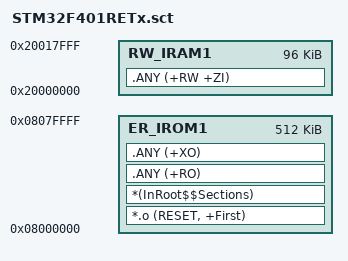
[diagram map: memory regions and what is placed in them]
; *************************************************************
; ** Scatter-Loading Description File generated by RTE CMSIS Plug-in **
; *************************************************************

LR_IROM1 0x8000000 0x80000 {    ; load region size_region
  ER_IROM1 0x8000000 0x80000 {  ; load address = execution address
   *.o (RESET, +First)
   *(InRoot$$Sections)
   .ANY (+RO)
   .ANY (+XO)
  }
  RW_IRAM1 0x20000000 0x18000 {
   .ANY (+RW +ZI)
  }
}

